# STM32WL5x_CM0P register map
File version: 1.9
CPU: CM0 r0p1, little endian, MPU, no FPU, 4 interrupt priority bits
Registers are 32-bit, read-write, reset 0x0 unless marked. A register's access mark holds for its fields unless they carry their own. Offsets are from the block's base; [hi:lo] are bit positions; {n}, {i} and the like mark numbered series.

## STK — SysTick timer
Base 0xE000E010
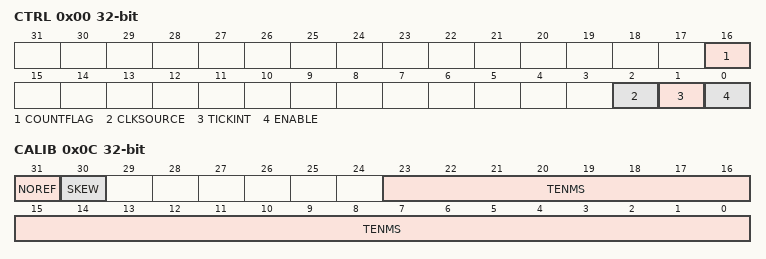
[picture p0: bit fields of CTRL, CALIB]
0x00 CTRL — SysTick control and status register
  [16] COUNTFLAG
  [2] CLKSOURCE — Clock source selection
  [1] TICKINT — SysTick exception request enable
  [0] ENABLE — Counter enable
0x04 LOAD — SysTick reload value register
  [23:0] RELOAD — RELOAD value
0x08 VAL — SysTick current value register
  [23:0] CURRENT — Current counter value
0x0C CALIB — SysTick calibration value register
  [31] NOREF — NOREF flag. Reads as zero
  [30] SKEW — SKEW flag: Indicates whether the TENMS value is exact
  [23:0] TENMS — Calibration value

## SYSCFG — System configuration controller
Base 0x40010000
0x00 MEMRMP — memory remap register
  [2:0] MEM_MODE — Memory mapping selection
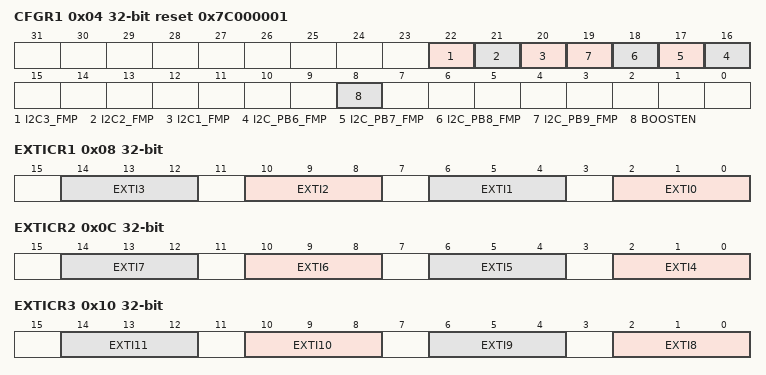
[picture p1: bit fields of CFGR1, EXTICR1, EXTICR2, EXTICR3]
0x04 CFGR1 reset 0x7C000001 — configuration register 1
  [22] I2C3_FMP — I2C3 Fast-mode Plus driving capability activation
  [21] I2C2_FMP — I2C2 Fast-mode Plus driving capability activation
  [20] I2C1_FMP — I2C1 Fast-mode Plus driving capability activation
  [n+10] I2C_PB{n}_FMP (n=6..9) — Fast-mode Plus (Fm+) driving capability activation on PB{n}
  [8] BOOSTEN — I/O analog switch voltage booster enable
0x08 EXTICR1 — external interrupt configuration register 1
  [4n+2:4n] EXTI{n} (n=0..3) — EXTI {n} configuration bits
0x0C EXTICR2 — external interrupt configuration register 2
  [4n-14:4n-16] EXTI{n} (n=4..7) — EXTI {n} configuration bits
0x10 EXTICR3 — external interrupt configuration register 3
  [4n-30:4n-32] EXTI{n} (n=8..11) — EXTI {n} configuration bits
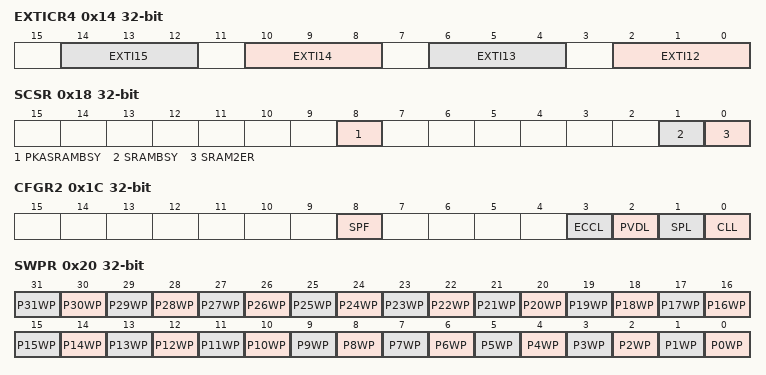
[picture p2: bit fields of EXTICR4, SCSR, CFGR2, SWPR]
0x14 EXTICR4 — external interrupt configuration register 4
  [4n-46:4n-48] EXTI{n} (n=12..15) — EXTI{n} configuration bits
0x18 SCSR access per field
  [8] PKASRAMBSY ro — PKA SRAM busy by erase operation
  [1] SRAMBSY ro — SRAM1, SRAM2 and PKA SRAM busy by erase operation
  [0] SRAM2ER rw — SRAM2 erase
0x1C CFGR2
  [8] SPF — SRAM2 parity error flag
  [3] ECCL — ECC Lock
  [2] PVDL — PVD lock enable bit
  [1] SPL — SRAM2 parity lock bit
  [0] CLL — CPU1 LOCKUP (Hardfault) output enable bit
0x20 SWPR
  [n] P{n}WP (n=0..31) — SRAM2 1Kbyte page {n} write protection
0x24 SKR wo
  [7:0] KEY — SRAM2 write protection key for software erase
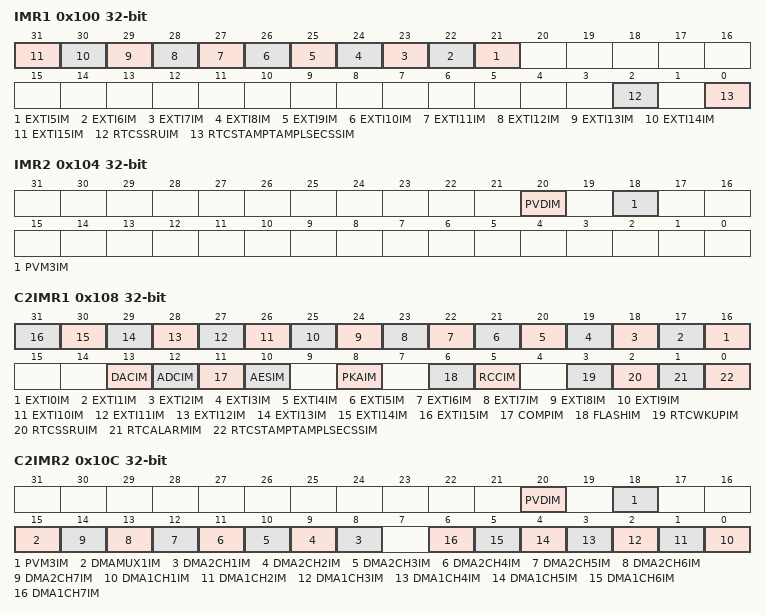
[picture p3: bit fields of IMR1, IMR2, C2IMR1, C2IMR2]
0x100 IMR1 — SYSCFG CPU1 interrupt mask register 1
  [n+16] EXTI{n}IM (n=5..15), [2] RTCSSRUIM, [0] RTCSTAMPTAMPLSECSSIM
0x104 IMR2 — SYSCFG CPU1 interrupt mask register 2
  [20] PVDIM, [18] PVM3IM
0x108 C2IMR1 — SYSCFG CPU2 interrupt mask register 1
  [n+16] EXTI{n}IM (n=0..15), [13] DACIM, [12] ADCIM, [11] COMPIM, [10] AESIM, [8] PKAIM, [6] FLASHIM, [5] RCCIM, [3] RTCWKUPIM, [2] RTCSSRUIM, [1] RTCALARMIM, [0] RTCSTAMPTAMPLSECSSIM
0x10C C2IMR2 — SYSCFG CPU2 interrupt mask register 2
  [20] PVDIM, [18] PVM3IM, [15] DMAMUX1IM, [n+7] DMA2CH{n}IM (n=1..7), [n-1] DMA1CH{n}IM (n=1..7)
0x208 RFDCR — radio debug control register
  [0] RFTBSEL — radio debug test bus selection

## SYSCFG_continue — System configuration controller
Base 0x40010100
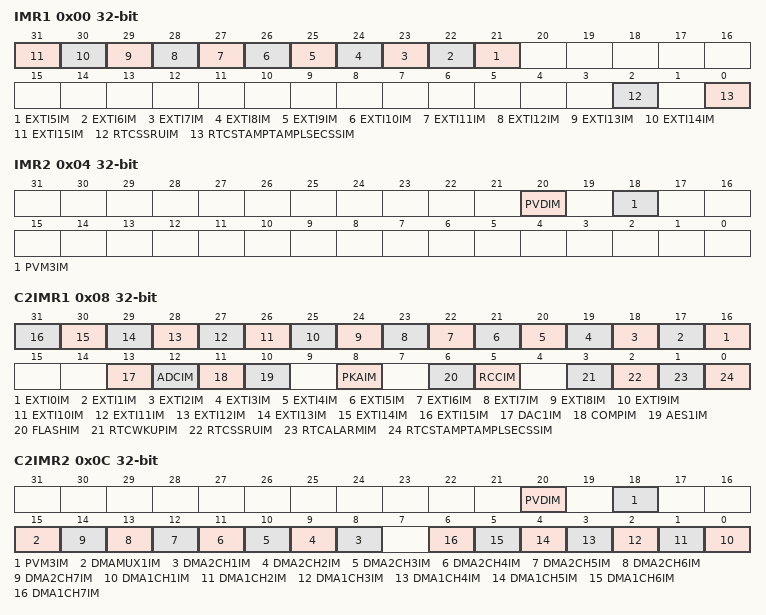
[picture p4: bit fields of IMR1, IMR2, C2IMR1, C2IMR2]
0x00 IMR1
  [n+16] EXTI{n}IM (n=5..15) — Peripheral EXTI{n} interrupt mask to CPU1
  [2] RTCSSRUIM
  [0] RTCSTAMPTAMPLSECSSIM
0x04 IMR2
  [20] PVDIM — Peripheral xxx interrupt mask to CPU1
  [18] PVM3IM — Peripheral xxx interrupt mask to CPU1
0x08 C2IMR1
  [n+16] EXTI{n}IM (n=0..15) — Peripheral EXTI{n} interrupt mask to CPU2
  [13] DAC1IM — Peripheral DAC1 interrupt mask to CPU2
  [12] ADCIM — Peripheral ADC interrupt mask to CPU2
  [11] COMPIM — Peripheral COMP interrupt mask to CPU2
  [10] AES1IM
  [8] PKAIM
  [6] FLASHIM — Peripheral FLASH interrupt mask to CPU2
  [5] RCCIM — Peripheral RCC interrupt mask to CPU2
  [3] RTCWKUPIM — Peripheral RTCWKUP interrupt mask to CPU2
  [2] RTCSSRUIM
  [1] RTCALARMIM — Peripheral RTCALARM interrupt mask to CPU2
  [0] RTCSTAMPTAMPLSECSSIM — Peripheral RTCSTAMPTAMPLSECSS interrupt mask to CPU2
0x0C C2IMR2
  [20] PVDIM — Peripheral PVD interrupt mask to CPU2
  [18] PVM3IM — Peripheral PVM3 interrupt mask to CPU2
  [15] DMAMUX1IM — Peripheral DMAMUX1 interrupt mask to CPU2
  [n+7] DMA2CH{n}IM (n=1..7) — Peripheral DMA2CH{n} interrupt mask to CPU2
  [n-1] DMA1CH{n}IM (n=1..7) — Peripheral DMA1CH{n} interrupt mask to CPU2
